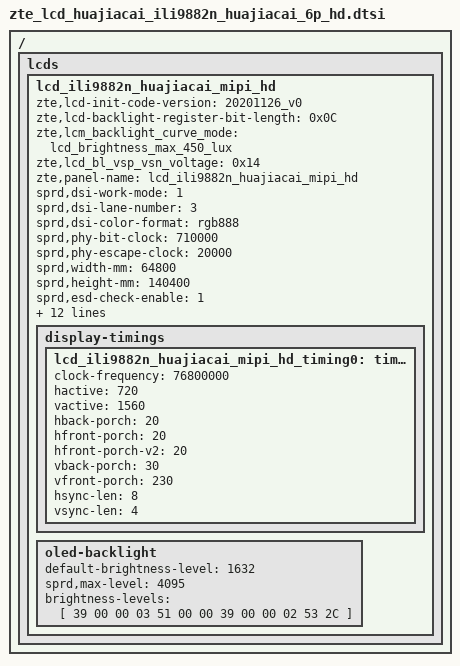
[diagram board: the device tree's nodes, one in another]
/ { lcds {
	lcd_ili9882n_huajiacai_mipi_hd: lcd_ili9882n_huajiacai_mipi_hd {
		zte,lcd-init-code-version = "20201126_v0";
		zte,lcd-backlight-register-bit-length = <0x0C>;
		zte,lcm_backlight_curve_mode = "lcd_brightness_max_450_lux";
		zte,lcd_bl_vsp_vsn_voltage = <0x14>;

		zte,panel-name = "lcd_ili9882n_huajiacai_mipi_hd";

		sprd,dsi-work-mode = <1>; /* video burst mode*/
		sprd,dsi-lane-number = <3>;
		sprd,dsi-color-format = "rgb888";

		sprd,phy-bit-clock = <710000>;	/* kbps */
		sprd,phy-escape-clock = <20000>;/* kHz */

		sprd,width-mm = <64800>;
		sprd,height-mm = <140400>;

		sprd,esd-check-enable = <1>;/* 0:close , 1:open */
		sprd,esd-check-mode = <1>;/* 0:REG ,1:TE  */
		sprd,esd-check-period = <1000>;
		sprd,esd-check-register = <0x0A>;
		sprd,esd-check-value = <0x9C>;
		sprd,reset-on-sequence = <1 10>, <0 12>, <1 35>;
		sprd,reset-off-sequence = <1 0>, <1 0>, <1 20>;
		sprd,initial-command = [
39 00 00 04 ff 98 82 01
39 00 00 02 00 46
39 00 00 02 01 16
39 00 00 02 02 10
39 00 00 02 03 10
39 00 00 02 08 80
39 00 00 02 09 12
39 00 00 02 0a 71
39 00 00 02 0b 00
39 00 00 02 14 8a
39 00 00 02 15 8a
39 00 00 02 0c 10
39 00 00 02 0d 10
39 00 00 02 0e 00
39 00 00 02 0f 00
39 00 00 02 10 01
39 00 00 02 11 01
39 00 00 02 12 01
39 00 00 02 24 00
39 00 00 02 25 09
39 00 00 02 26 10
39 00 00 02 27 10
39 00 00 02 31 21
39 00 00 02 32 07
39 00 00 02 33 01
39 00 00 02 34 00
39 00 00 02 35 02
39 00 00 02 36 07
39 00 00 02 37 07
39 00 00 02 38 07
39 00 00 02 39 07
39 00 00 02 3a 17
39 00 00 02 3b 15
39 00 00 02 3c 07
39 00 00 02 3d 07
39 00 00 02 3e 13
39 00 00 02 3f 11
39 00 00 02 40 09
39 00 00 02 41 07
39 00 00 02 42 07
39 00 00 02 43 07
39 00 00 02 44 07
39 00 00 02 45 07
39 00 00 02 46 07
39 00 00 02 47 20
39 00 00 02 48 07
39 00 00 02 49 01
39 00 00 02 4a 00
39 00 00 02 4b 02
39 00 00 02 4c 07
39 00 00 02 4d 07
39 00 00 02 4e 07
39 00 00 02 4f 07
39 00 00 02 50 16
39 00 00 02 51 14
39 00 00 02 52 07
39 00 00 02 53 07
39 00 00 02 54 12
39 00 00 02 55 10
39 00 00 02 56 08
39 00 00 02 57 07
39 00 00 02 58 07
39 00 00 02 59 07
39 00 00 02 5a 07
39 00 00 02 5b 07
39 00 00 02 5c 07
39 00 00 02 61 08
39 00 00 02 62 07
39 00 00 02 63 01
39 00 00 02 64 00
39 00 00 02 65 02
39 00 00 02 66 07
39 00 00 02 67 07
39 00 00 02 68 07
39 00 00 02 69 07
39 00 00 02 6a 10
39 00 00 02 6b 12
39 00 00 02 6c 07
39 00 00 02 6d 07
39 00 00 02 6e 14
39 00 00 02 6f 16
39 00 00 02 70 20
39 00 00 02 71 07
39 00 00 02 72 07
39 00 00 02 73 07
39 00 00 02 74 07
39 00 00 02 75 07
39 00 00 02 76 07
39 00 00 02 77 09
39 00 00 02 78 07
39 00 00 02 79 01
39 00 00 02 7a 00
39 00 00 02 7b 02
39 00 00 02 7c 07
39 00 00 02 7d 07
39 00 00 02 7e 07
39 00 00 02 7f 07
39 00 00 02 80 11
39 00 00 02 81 13
39 00 00 02 82 07
39 00 00 02 83 07
39 00 00 02 84 15
39 00 00 02 85 17
39 00 00 02 86 21
39 00 00 02 87 07
39 00 00 02 88 07
39 00 00 02 89 07
39 00 00 02 8a 07
39 00 00 02 8b 07
39 00 00 02 8c 07
39 00 00 02 a0 01
39 00 00 02 a1 10
39 00 00 02 a2 08
39 00 00 02 a5 10
39 00 00 02 a6 10
39 00 00 02 a7 00
39 00 00 02 a8 00
39 00 00 02 a9 09
39 00 00 02 aa 09
39 00 00 02 b9 40
39 00 00 02 d0 01
39 00 00 02 d1 00
39 00 00 02 dc 35
39 00 00 02 dd 42
39 00 00 02 e2 00
39 00 00 02 e6 22
39 00 00 02 e7 54
39 00 00 04 ff 98 82 02
39 00 00 02 f1 1c
39 00 00 02 4b 5a
39 00 00 02 50 ca
39 00 00 02 51 00
39 00 00 02 06 90
39 00 00 02 0b a0
39 00 00 02 0c 00
39 00 00 02 0d 14
39 00 00 02 0e fa
39 00 00 02 4e 11
39 00 00 04 ff 98 82 05
39 00 00 02 03 00
39 00 00 02 04 da
39 00 00 02 58 63
39 00 00 02 63 7e
39 00 00 02 64 7e
39 00 00 02 68 a1
39 00 00 02 69 a7
39 00 00 02 6a a1
39 00 00 02 6b 93
39 00 00 02 85 37
39 00 00 02 46 00
39 00 00 02 23 42
39 00 00 02 24 52
39 00 00 04 ff 98 82 06
39 00 00 02 06 a4
39 00 00 02 d9 10
39 00 00 02 c0 18
39 00 00 02 c1 16
39 00 00 04 ff 98 82 08
39 00 00 1c e0 00 24 83 bb fb 55 2e 54 80 a2 a9 d8 02 28 4d aa 74 a4 c4 ec ff 0e 3a 70 9c 03 ec
39 00 00 1c e1 00 24 83 bb fb 55 2e 54 80 a2 a9 d8 02 28 4d aa 74 a4 c4 ec ff 0e 3a 70 9c 03 ec
39 00 00 04 ff 98 82 0b
39 00 00 02 9a 44
39 00 00 02 9b a0
39 00 00 02 9c 03
39 00 00 02 9d 03
39 00 00 02 9e 73
39 00 00 02 9f 73
39 00 00 02 ab e0
39 00 00 04 ff 98 82 0e
39 00 00 02 11 10
39 00 00 02 13 14
39 00 00 02 00 a0
39 00 00 04 FF 98 82 03
23 00 00 02 83 20
23 00 00 02 84 00
39 00 00 04 FF 98 82 00
39 00 00 03 68 04 00
13 78 00 01 11
13 28 00 01 29
23 01 00 02 35 00
39 01 00 03 51 00 00
23 01 00 02 53 24
23 01 00 02 55 00
39 01 00 03 5E 00 40
];
		sprd,sleep-in-command = [
			39 00 00 04 FF 98 82 00
			13 0A 00 01 28
			13 78 00 01 10
			];
		sprd,sleep-out-command = [
			13 78 00 01 11
			13 64 00 01 29
			];

		display-timings {
			lcd_ili9882n_huajiacai_mipi_hd_timing0: timing0 {
			clock-frequency = <76800000>;
			hactive = <720>;
			vactive = <1560>;
			hback-porch = <20>;
			hfront-porch = <20>;
			hfront-porch-v2 = <20>;
			vback-porch = <30>;
			vfront-porch = <230>;
			hsync-len = <8>;
			vsync-len = <4>;
			};
		};
		oled-backlight {
			default-brightness-level = <1632>;
			sprd,max-level = <4095>;
			brightness-levels = [
				39 00 00 03 51 00 00
				39 00 00 02 53 2C
			];
		};
	};
};};

